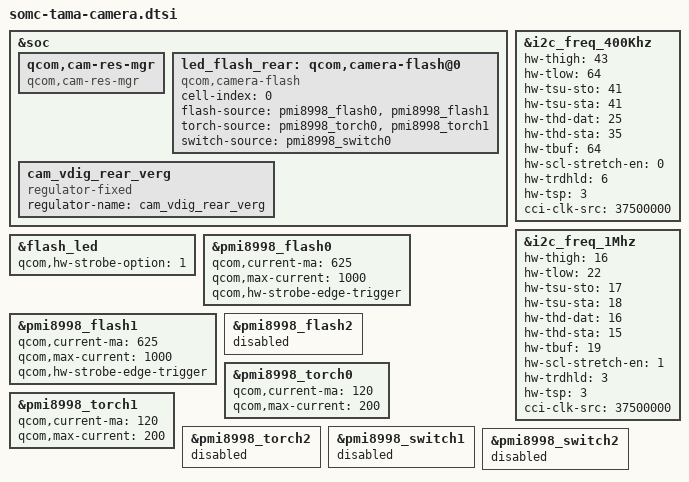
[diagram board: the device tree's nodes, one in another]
&soc {
	qcom,cam-res-mgr {
		compatible = "qcom,cam-res-mgr";
		status = "ok";
	};

	led_flash_rear: qcom,camera-flash@0 {
		cell-index = <0>;
		compatible = "qcom,camera-flash";
		flash-source = <&pmi8998_flash0 &pmi8998_flash1>;
		torch-source = <&pmi8998_torch0 &pmi8998_torch1>;
		switch-source = <&pmi8998_switch0>;
		status = "ok";
	};

	cam_vdig_rear_verg: cam_vdig_rear_verg {
		compatible = "regulator-fixed";
		regulator-name = "cam_vdig_rear_verg";
	};
};

&i2c_freq_400Khz {
	hw-thigh = <43>;
	hw-tlow = <64>;
	hw-tsu-sto = <41>;
	hw-tsu-sta = <41>;
	hw-thd-dat = <25>;
	hw-thd-sta = <35>;
	hw-tbuf = <64>;
	hw-scl-stretch-en = <0>;
	hw-trdhld = <6>;
	hw-tsp = <3>;
	cci-clk-src = <37500000>;
	status = "ok";
};

&i2c_freq_1Mhz {
	hw-thigh = <16>;
	hw-tlow = <22>;
	hw-tsu-sto = <17>;
	hw-tsu-sta = <18>;
	hw-thd-dat = <16>;
	hw-thd-sta = <15>;
	hw-tbuf = <19>;
	hw-scl-stretch-en = <1>;
	hw-trdhld = <3>;
	hw-tsp = <3>;
	cci-clk-src = <37500000>;
	status = "ok";
};

&flash_led {
	qcom,hw-strobe-option = <1>;
};

&pmi8998_flash0 {
	qcom,current-ma = <625>;
	qcom,max-current = <1000>;
	qcom,hw-strobe-edge-trigger;
};

&pmi8998_flash1 {
	qcom,current-ma = <625>;
	qcom,max-current = <1000>;
	qcom,hw-strobe-edge-trigger;
};

&pmi8998_flash2 {
	status = "disabled";
};

&pmi8998_torch0 {
	qcom,current-ma = <120>;
	qcom,max-current = <200>;
};

&pmi8998_torch1 {
	qcom,current-ma = <120>;
	qcom,max-current = <200>;
};

&pmi8998_torch2 {
	status = "disabled";
};

&pmi8998_switch1 {
	status = "disabled";
};

&pmi8998_switch2 {
	status = "disabled";
};
